# SMS_TIFS_ECC_AGGR_0_ECC_AGGR_43700000h register map
Vendor: Texas Instruments
Peripheral module from a debugger description file (folder AM275x).
Registers are 32-bit, access not given, reset 0x0 unless marked. A register's access mark holds for its fields unless they carry their own. Offsets are as the file gives them; lines under a group give offsets from that group; [hi:lo] are bit positions; {n}, {i} and the like mark numbered series; 'fields as' and 'values as' point back to an identical list; <NAME> marks a mode.

## ECC_AGGR
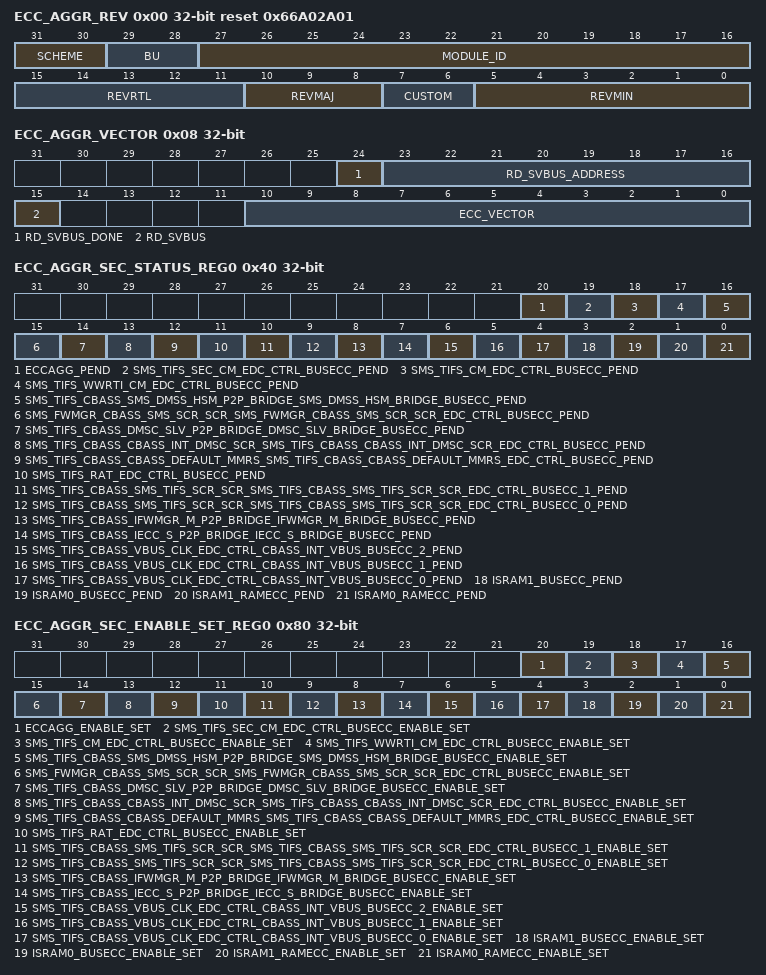
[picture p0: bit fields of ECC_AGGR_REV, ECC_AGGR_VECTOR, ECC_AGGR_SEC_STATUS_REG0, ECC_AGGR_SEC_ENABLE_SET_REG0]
0x00 ECC_AGGR_REV ro reset 0x66A02A01 — Revision parameters
  [31:30] SCHEME — Scheme Reset Source: sms_custom_rst_mod_g_rst_n
  [29:28] BU — Business Unit Reset Source: sms_custom_rst_mod_g_rst_n
  [27:16] MODULE_ID — Module ID Reset Source: sms_custom_rst_mod_g_rst_n
  [15:11] REVRTL — RTL version Reset Source: sms_custom_rst_mod_g_rst_n
  [10:8] REVMAJ — Major version Reset Source: sms_custom_rst_mod_g_rst_n
  [7:6] CUSTOM — Custom version Reset Source: sms_custom_rst_mod_g_rst_n
  [5:0] REVMIN — Minor version Reset Source: sms_custom_rst_mod_g_rst_n
0x08 ECC_AGGR_VECTOR — ECC Vector Register
  [24] RD_SVBUS_DONE — Status to indicate if read on serial VBUS is complete, write of any value will clear this bit. Reset Source: sms_custom_rst_mod_g_rst_n (access R/W1TC)
  [23:16] RD_SVBUS_ADDRESS rw — Read address Reset Source: sms_custom_rst_mod_g_rst_n
  [15] RD_SVBUS — Write 1 to trigger a read on the serial VBUS Reset Source: sms_custom_rst_mod_g_rst_n (access R/W1TS)
  [10:0] ECC_VECTOR rw — Value written to select the corresponding ECC RAM for control or status Reset Source: sms_custom_rst_mod_g_rst_n
0x0C ECC_AGGR_STAT ro reset 0x15 — Misc Status
  [10:0] NUM_RAMS — Indicates the number of RAMS serviced by the ECC aggregator Reset Source: sms_custom_rst_mod_g_rst_n
0x10 ECC_AGGR_RESERVED_SVBUS_j rw — Reference other documents that contain the ECC RAM wrapper and EDC controller serial vbus register sets.
  [31:0] DATA — Serial VBUS register data Reset Source: sms_custom_rst_mod_g_rst_n
0x3C ECC_AGGR_SEC_EOI_REG — EOI Register
  [0] EOI_WR — EOI Register Reset Source: sms_custom_rst_mod_g_rst_n (access R/W1TS)
0x40 ECC_AGGR_SEC_STATUS_REG0 — Interrupt Status Register 0
  [20] ECCAGG_PEND — Interrupt Pending Status for eccagg_pend Reset Source: sms_custom_rst_mod_g_rst_n (access R/W1TS)
  [19] SMS_TIFS_SEC_CM_EDC_CTRL_BUSECC_PEND — Interrupt Pending Status for sms_tifs_sec_cm_edc_ctrl_busecc_pend Reset Source: sms_custom_rst_mod_g_rst_n (access R/W1TS)
  [18] SMS_TIFS_CM_EDC_CTRL_BUSECC_PEND — Interrupt Pending Status for sms_tifs_cm_edc_ctrl_busecc_pend Reset Source: sms_custom_rst_mod_g_rst_n (access R/W1TS)
  [17] SMS_TIFS_WWRTI_CM_EDC_CTRL_BUSECC_PEND — Interrupt Pending Status for sms_tifs_wwrti_cm_edc_ctrl_busecc_pend Reset Source: sms_custom_rst_mod_g_rst_n (access R/W1TS)
  [16] SMS_TIFS_CBASS_SMS_DMSS_HSM_P2P_BRIDGE_SMS_DMSS_HSM_BRIDGE_BUSECC_PEND — Interrupt Pending Status for sms_tifs_cbass_sms_dmss_hsm_p2p_bridge_sms_dmss_hsm_bridge_busecc_pend Reset Source: sms_custom_rst_mod_g_rst_n (access R/W1TS)
  [15] SMS_FWMGR_CBASS_SMS_SCR_SCR_SMS_FWMGR_CBASS_SMS_SCR_SCR_EDC_CTRL_BUSECC_PEND — Interrupt Pending Status for sms_fwmgr_cbass_sms_scr_scr_sms_fwmgr_cbass_sms_scr_scr_edc_ctrl_busecc_pend Reset Source: sms_custom_rst_mod_g_rst_n (access R/W1TS)
  [14] SMS_TIFS_CBASS_DMSC_SLV_P2P_BRIDGE_DMSC_SLV_BRIDGE_BUSECC_PEND — Interrupt Pending Status for sms_tifs_cbass_dmsc_slv_p2p_bridge_dmsc_slv_bridge_busecc_pend Reset Source: sms_custom_rst_mod_g_rst_n (access R/W1TS)
  [13] SMS_TIFS_CBASS_CBASS_INT_DMSC_SCR_SMS_TIFS_CBASS_CBASS_INT_DMSC_SCR_EDC_CTRL_BUSECC_PEND — Interrupt Pending Status for sms_tifs_cbass_cbass_int_dmsc_scr_sms_tifs_cbass_cbass_int_dmsc_scr_edc_ctrl_busecc_pend Reset Source: sms_custom_rst_mod_g_rst_n (access R/W1TS)
  [12] SMS_TIFS_CBASS_CBASS_DEFAULT_MMRS_SMS_TIFS_CBASS_CBASS_DEFAULT_MMRS_EDC_CTRL_BUSECC_PEND — Interrupt Pending Status for sms_tifs_cbass_cbass_default_mmrs_sms_tifs_cbass_cbass_default_mmrs_edc_ctrl_busecc_pend Reset Source: sms_custom_rst_mod_g_rst_n (access R/W1TS)
  [11] SMS_TIFS_RAT_EDC_CTRL_BUSECC_PEND — Interrupt Pending Status for sms_tifs_rat_edc_ctrl_busecc_pend Reset Source: sms_custom_rst_mod_g_rst_n (access R/W1TS)
  [10] SMS_TIFS_CBASS_SMS_TIFS_SCR_SCR_SMS_TIFS_CBASS_SMS_TIFS_SCR_SCR_EDC_CTRL_BUSECC_1_PEND — Interrupt Pending Status for sms_tifs_cbass_sms_tifs_scr_scr_sms_tifs_cbass_sms_tifs_scr_scr_edc_ctrl_busecc_1_pend Reset Source: sms_custom_rst_mod_g_rst_n (access R/W1TS)
  [9] SMS_TIFS_CBASS_SMS_TIFS_SCR_SCR_SMS_TIFS_CBASS_SMS_TIFS_SCR_SCR_EDC_CTRL_BUSECC_0_PEND — Interrupt Pending Status for sms_tifs_cbass_sms_tifs_scr_scr_sms_tifs_cbass_sms_tifs_scr_scr_edc_ctrl_busecc_0_pend Reset Source: sms_custom_rst_mod_g_rst_n (access R/W1TS)
  [8] SMS_TIFS_CBASS_IFWMGR_M_P2P_BRIDGE_IFWMGR_M_BRIDGE_BUSECC_PEND — Interrupt Pending Status for sms_tifs_cbass_Ifwmgr_m_p2p_bridge_Ifwmgr_m_bridge_busecc_pend Reset Source: sms_custom_rst_mod_g_rst_n (access R/W1TS)
  [7] SMS_TIFS_CBASS_IECC_S_P2P_BRIDGE_IECC_S_BRIDGE_BUSECC_PEND — Interrupt Pending Status for sms_tifs_cbass_Iecc_s_p2p_bridge_Iecc_s_bridge_busecc_pend Reset Source: sms_custom_rst_mod_g_rst_n (access R/W1TS)
  [6] SMS_TIFS_CBASS_VBUS_CLK_EDC_CTRL_CBASS_INT_VBUS_BUSECC_2_PEND — Interrupt Pending Status for sms_tifs_cbass_vbus_clk_edc_ctrl_cbass_int_vbus_busecc_2_pend Reset Source: sms_custom_rst_mod_g_rst_n (access R/W1TS)
  [5] SMS_TIFS_CBASS_VBUS_CLK_EDC_CTRL_CBASS_INT_VBUS_BUSECC_1_PEND — Interrupt Pending Status for sms_tifs_cbass_vbus_clk_edc_ctrl_cbass_int_vbus_busecc_1_pend Reset Source: sms_custom_rst_mod_g_rst_n (access R/W1TS)
  [4] SMS_TIFS_CBASS_VBUS_CLK_EDC_CTRL_CBASS_INT_VBUS_BUSECC_0_PEND — Interrupt Pending Status for sms_tifs_cbass_vbus_clk_edc_ctrl_cbass_int_vbus_busecc_0_pend Reset Source: sms_custom_rst_mod_g_rst_n (access R/W1TS)
  [3] ISRAM1_BUSECC_PEND — Interrupt Pending Status for Isram1_busecc_pend Reset Source: sms_custom_rst_mod_g_rst_n (access R/W1TS)
  [2] ISRAM0_BUSECC_PEND — Interrupt Pending Status for Isram0_busecc_pend Reset Source: sms_custom_rst_mod_g_rst_n (access R/W1TS)
  [1] ISRAM1_RAMECC_PEND — Interrupt Pending Status for Isram1_ramecc_pend Reset Source: sms_custom_rst_mod_g_rst_n (access R/W1TS)
  [0] ISRAM0_RAMECC_PEND — Interrupt Pending Status for Isram0_ramecc_pend Reset Source: sms_custom_rst_mod_g_rst_n (access R/W1TS)
0x80 ECC_AGGR_SEC_ENABLE_SET_REG0 — Interrupt Enable Set Register 0
  [20] ECCAGG_ENABLE_SET — Interrupt Enable Set Register for eccagg_pend Reset Source: sms_custom_rst_mod_g_rst_n (access R/W1TS)
  [19] SMS_TIFS_SEC_CM_EDC_CTRL_BUSECC_ENABLE_SET — Interrupt Enable Set Register for sms_tifs_sec_cm_edc_ctrl_busecc_pend Reset Source: sms_custom_rst_mod_g_rst_n (access R/W1TS)
  [18] SMS_TIFS_CM_EDC_CTRL_BUSECC_ENABLE_SET — Interrupt Enable Set Register for sms_tifs_cm_edc_ctrl_busecc_pend Reset Source: sms_custom_rst_mod_g_rst_n (access R/W1TS)
  [17] SMS_TIFS_WWRTI_CM_EDC_CTRL_BUSECC_ENABLE_SET — Interrupt Enable Set Register for sms_tifs_wwrti_cm_edc_ctrl_busecc_pend Reset Source: sms_custom_rst_mod_g_rst_n (access R/W1TS)
  [16] SMS_TIFS_CBASS_SMS_DMSS_HSM_P2P_BRIDGE_SMS_DMSS_HSM_BRIDGE_BUSECC_ENABLE_SET — Interrupt Enable Set Register for sms_tifs_cbass_sms_dmss_hsm_p2p_bridge_sms_dmss_hsm_bridge_busecc_pend Reset Source: sms_custom_rst_mod_g_rst_n (access R/W1TS)
  [15] SMS_FWMGR_CBASS_SMS_SCR_SCR_SMS_FWMGR_CBASS_SMS_SCR_SCR_EDC_CTRL_BUSECC_ENABLE_SET — Interrupt Enable Set Register for sms_fwmgr_cbass_sms_scr_scr_sms_fwmgr_cbass_sms_scr_scr_edc_ctrl_busecc_pend Reset Source: sms_custom_rst_mod_g_rst_n (access R/W1TS)
  [14] SMS_TIFS_CBASS_DMSC_SLV_P2P_BRIDGE_DMSC_SLV_BRIDGE_BUSECC_ENABLE_SET — Interrupt Enable Set Register for sms_tifs_cbass_dmsc_slv_p2p_bridge_dmsc_slv_bridge_busecc_pend Reset Source: sms_custom_rst_mod_g_rst_n (access R/W1TS)
  [13] SMS_TIFS_CBASS_CBASS_INT_DMSC_SCR_SMS_TIFS_CBASS_CBASS_INT_DMSC_SCR_EDC_CTRL_BUSECC_ENABLE_SET — Interrupt Enable Set Register for sms_tifs_cbass_cbass_int_dmsc_scr_sms_tifs_cbass_cbass_int_dmsc_scr_edc_ctrl_busecc_pend Reset Source: sms_custom_rst_mod_g_rst_n (access R/W1TS)
  [12] SMS_TIFS_CBASS_CBASS_DEFAULT_MMRS_SMS_TIFS_CBASS_CBASS_DEFAULT_MMRS_EDC_CTRL_BUSECC_ENABLE_SET — Interrupt Enable Set Register for sms_tifs_cbass_cbass_default_mmrs_sms_tifs_cbass_cbass_default_mmrs_edc_ctrl_busecc_pend Reset Source: sms_custom_rst_mod_g_rst_n (access R/W1TS)
  [11] SMS_TIFS_RAT_EDC_CTRL_BUSECC_ENABLE_SET — Interrupt Enable Set Register for sms_tifs_rat_edc_ctrl_busecc_pend Reset Source: sms_custom_rst_mod_g_rst_n (access R/W1TS)
  [10] SMS_TIFS_CBASS_SMS_TIFS_SCR_SCR_SMS_TIFS_CBASS_SMS_TIFS_SCR_SCR_EDC_CTRL_BUSECC_1_ENABLE_SET — Interrupt Enable Set Register for sms_tifs_cbass_sms_tifs_scr_scr_sms_tifs_cbass_sms_tifs_scr_scr_edc_ctrl_busecc_1_pend Reset Source: sms_custom_rst_mod_g_rst_n (access R/W1TS)
  [9] SMS_TIFS_CBASS_SMS_TIFS_SCR_SCR_SMS_TIFS_CBASS_SMS_TIFS_SCR_SCR_EDC_CTRL_BUSECC_0_ENABLE_SET — Interrupt Enable Set Register for sms_tifs_cbass_sms_tifs_scr_scr_sms_tifs_cbass_sms_tifs_scr_scr_edc_ctrl_busecc_0_pend Reset Source: sms_custom_rst_mod_g_rst_n (access R/W1TS)
  [8] SMS_TIFS_CBASS_IFWMGR_M_P2P_BRIDGE_IFWMGR_M_BRIDGE_BUSECC_ENABLE_SET — Interrupt Enable Set Register for sms_tifs_cbass_Ifwmgr_m_p2p_bridge_Ifwmgr_m_bridge_busecc_pend Reset Source: sms_custom_rst_mod_g_rst_n (access R/W1TS)
  [7] SMS_TIFS_CBASS_IECC_S_P2P_BRIDGE_IECC_S_BRIDGE_BUSECC_ENABLE_SET — Interrupt Enable Set Register for sms_tifs_cbass_Iecc_s_p2p_bridge_Iecc_s_bridge_busecc_pend Reset Source: sms_custom_rst_mod_g_rst_n (access R/W1TS)
  [6] SMS_TIFS_CBASS_VBUS_CLK_EDC_CTRL_CBASS_INT_VBUS_BUSECC_2_ENABLE_SET — Interrupt Enable Set Register for sms_tifs_cbass_vbus_clk_edc_ctrl_cbass_int_vbus_busecc_2_pend Reset Source: sms_custom_rst_mod_g_rst_n (access R/W1TS)
  [5] SMS_TIFS_CBASS_VBUS_CLK_EDC_CTRL_CBASS_INT_VBUS_BUSECC_1_ENABLE_SET — Interrupt Enable Set Register for sms_tifs_cbass_vbus_clk_edc_ctrl_cbass_int_vbus_busecc_1_pend Reset Source: sms_custom_rst_mod_g_rst_n (access R/W1TS)
  [4] SMS_TIFS_CBASS_VBUS_CLK_EDC_CTRL_CBASS_INT_VBUS_BUSECC_0_ENABLE_SET — Interrupt Enable Set Register for sms_tifs_cbass_vbus_clk_edc_ctrl_cbass_int_vbus_busecc_0_pend Reset Source: sms_custom_rst_mod_g_rst_n (access R/W1TS)
  [3] ISRAM1_BUSECC_ENABLE_SET — Interrupt Enable Set Register for Isram1_busecc_pend Reset Source: sms_custom_rst_mod_g_rst_n (access R/W1TS)
  [2] ISRAM0_BUSECC_ENABLE_SET — Interrupt Enable Set Register for Isram0_busecc_pend Reset Source: sms_custom_rst_mod_g_rst_n (access R/W1TS)
  [1] ISRAM1_RAMECC_ENABLE_SET — Interrupt Enable Set Register for Isram1_ramecc_pend Reset Source: sms_custom_rst_mod_g_rst_n (access R/W1TS)
  [0] ISRAM0_RAMECC_ENABLE_SET — Interrupt Enable Set Register for Isram0_ramecc_pend Reset Source: sms_custom_rst_mod_g_rst_n (access R/W1TS)
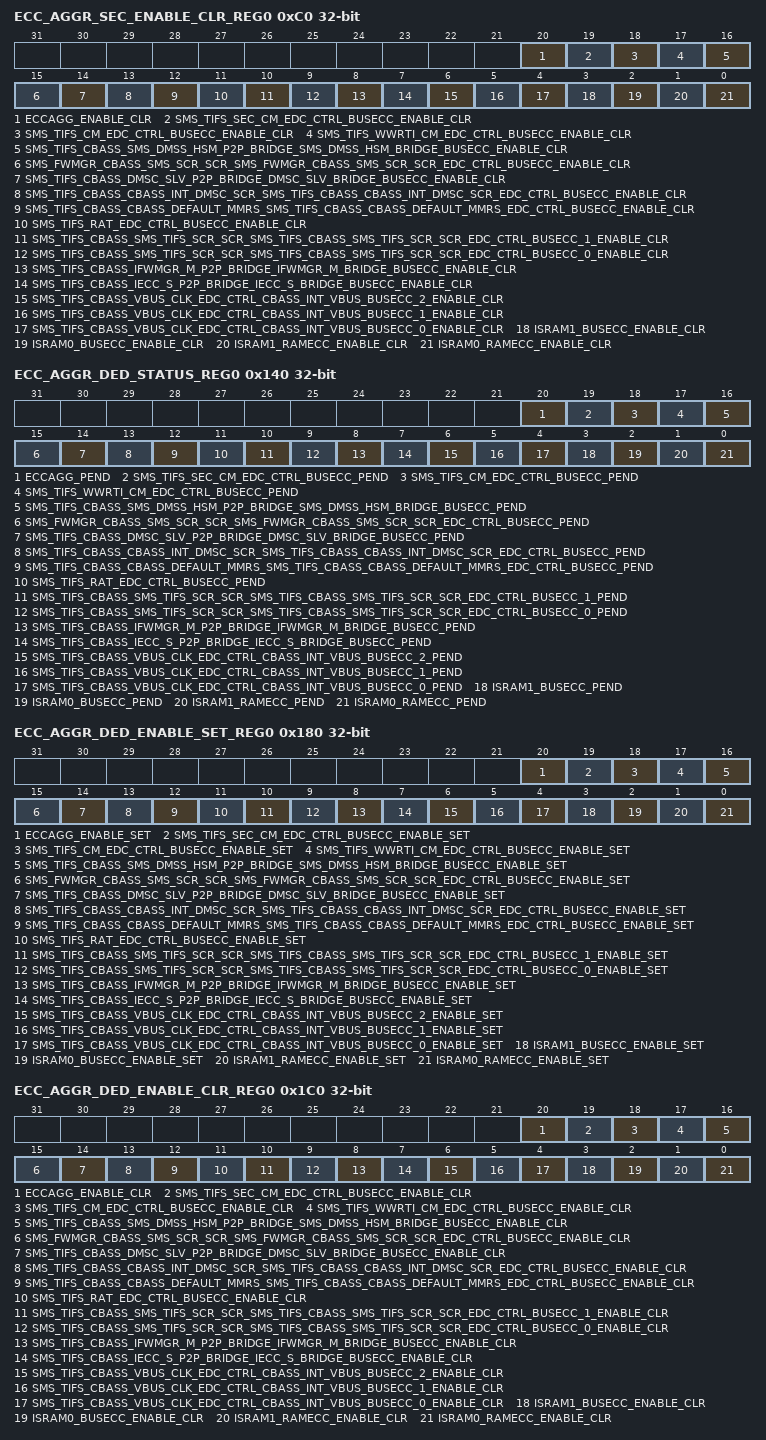
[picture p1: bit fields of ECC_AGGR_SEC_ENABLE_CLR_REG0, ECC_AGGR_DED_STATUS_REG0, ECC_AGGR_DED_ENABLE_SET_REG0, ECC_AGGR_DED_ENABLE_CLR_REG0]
0xC0 ECC_AGGR_SEC_ENABLE_CLR_REG0 — Interrupt Enable Clear Register 0
  [20] ECCAGG_ENABLE_CLR — Interrupt Enable Clear Register for eccagg_pend Reset Source: sms_custom_rst_mod_g_rst_n (access R/W1TC)
  [19] SMS_TIFS_SEC_CM_EDC_CTRL_BUSECC_ENABLE_CLR — Interrupt Enable Clear Register for sms_tifs_sec_cm_edc_ctrl_busecc_pend Reset Source: sms_custom_rst_mod_g_rst_n (access R/W1TC)
  [18] SMS_TIFS_CM_EDC_CTRL_BUSECC_ENABLE_CLR — Interrupt Enable Clear Register for sms_tifs_cm_edc_ctrl_busecc_pend Reset Source: sms_custom_rst_mod_g_rst_n (access R/W1TC)
  [17] SMS_TIFS_WWRTI_CM_EDC_CTRL_BUSECC_ENABLE_CLR — Interrupt Enable Clear Register for sms_tifs_wwrti_cm_edc_ctrl_busecc_pend Reset Source: sms_custom_rst_mod_g_rst_n (access R/W1TC)
  [16] SMS_TIFS_CBASS_SMS_DMSS_HSM_P2P_BRIDGE_SMS_DMSS_HSM_BRIDGE_BUSECC_ENABLE_CLR — Interrupt Enable Clear Register for sms_tifs_cbass_sms_dmss_hsm_p2p_bridge_sms_dmss_hsm_bridge_busecc_pend Reset Source: sms_custom_rst_mod_g_rst_n (access R/W1TC)
  [15] SMS_FWMGR_CBASS_SMS_SCR_SCR_SMS_FWMGR_CBASS_SMS_SCR_SCR_EDC_CTRL_BUSECC_ENABLE_CLR — Interrupt Enable Clear Register for sms_fwmgr_cbass_sms_scr_scr_sms_fwmgr_cbass_sms_scr_scr_edc_ctrl_busecc_pend Reset Source: sms_custom_rst_mod_g_rst_n (access R/W1TC)
  [14] SMS_TIFS_CBASS_DMSC_SLV_P2P_BRIDGE_DMSC_SLV_BRIDGE_BUSECC_ENABLE_CLR — Interrupt Enable Clear Register for sms_tifs_cbass_dmsc_slv_p2p_bridge_dmsc_slv_bridge_busecc_pend Reset Source: sms_custom_rst_mod_g_rst_n (access R/W1TC)
  [13] SMS_TIFS_CBASS_CBASS_INT_DMSC_SCR_SMS_TIFS_CBASS_CBASS_INT_DMSC_SCR_EDC_CTRL_BUSECC_ENABLE_CLR — Interrupt Enable Clear Register for sms_tifs_cbass_cbass_int_dmsc_scr_sms_tifs_cbass_cbass_int_dmsc_scr_edc_ctrl_busecc_pend Reset Source: sms_custom_rst_mod_g_rst_n (access R/W1TC)
  [12] SMS_TIFS_CBASS_CBASS_DEFAULT_MMRS_SMS_TIFS_CBASS_CBASS_DEFAULT_MMRS_EDC_CTRL_BUSECC_ENABLE_CLR — Interrupt Enable Clear Register for sms_tifs_cbass_cbass_default_mmrs_sms_tifs_cbass_cbass_default_mmrs_edc_ctrl_busecc_pend Reset Source: sms_custom_rst_mod_g_rst_n (access R/W1TC)
  [11] SMS_TIFS_RAT_EDC_CTRL_BUSECC_ENABLE_CLR — Interrupt Enable Clear Register for sms_tifs_rat_edc_ctrl_busecc_pend Reset Source: sms_custom_rst_mod_g_rst_n (access R/W1TC)
  [10] SMS_TIFS_CBASS_SMS_TIFS_SCR_SCR_SMS_TIFS_CBASS_SMS_TIFS_SCR_SCR_EDC_CTRL_BUSECC_1_ENABLE_CLR — Interrupt Enable Clear Register for sms_tifs_cbass_sms_tifs_scr_scr_sms_tifs_cbass_sms_tifs_scr_scr_edc_ctrl_busecc_1_pend Reset Source: sms_custom_rst_mod_g_rst_n (access R/W1TC)
  [9] SMS_TIFS_CBASS_SMS_TIFS_SCR_SCR_SMS_TIFS_CBASS_SMS_TIFS_SCR_SCR_EDC_CTRL_BUSECC_0_ENABLE_CLR — Interrupt Enable Clear Register for sms_tifs_cbass_sms_tifs_scr_scr_sms_tifs_cbass_sms_tifs_scr_scr_edc_ctrl_busecc_0_pend Reset Source: sms_custom_rst_mod_g_rst_n (access R/W1TC)
  [8] SMS_TIFS_CBASS_IFWMGR_M_P2P_BRIDGE_IFWMGR_M_BRIDGE_BUSECC_ENABLE_CLR — Interrupt Enable Clear Register for sms_tifs_cbass_Ifwmgr_m_p2p_bridge_Ifwmgr_m_bridge_busecc_pend Reset Source: sms_custom_rst_mod_g_rst_n (access R/W1TC)
  [7] SMS_TIFS_CBASS_IECC_S_P2P_BRIDGE_IECC_S_BRIDGE_BUSECC_ENABLE_CLR — Interrupt Enable Clear Register for sms_tifs_cbass_Iecc_s_p2p_bridge_Iecc_s_bridge_busecc_pend Reset Source: sms_custom_rst_mod_g_rst_n (access R/W1TC)
  [6] SMS_TIFS_CBASS_VBUS_CLK_EDC_CTRL_CBASS_INT_VBUS_BUSECC_2_ENABLE_CLR — Interrupt Enable Clear Register for sms_tifs_cbass_vbus_clk_edc_ctrl_cbass_int_vbus_busecc_2_pend Reset Source: sms_custom_rst_mod_g_rst_n (access R/W1TC)
  [5] SMS_TIFS_CBASS_VBUS_CLK_EDC_CTRL_CBASS_INT_VBUS_BUSECC_1_ENABLE_CLR — Interrupt Enable Clear Register for sms_tifs_cbass_vbus_clk_edc_ctrl_cbass_int_vbus_busecc_1_pend Reset Source: sms_custom_rst_mod_g_rst_n (access R/W1TC)
  [4] SMS_TIFS_CBASS_VBUS_CLK_EDC_CTRL_CBASS_INT_VBUS_BUSECC_0_ENABLE_CLR — Interrupt Enable Clear Register for sms_tifs_cbass_vbus_clk_edc_ctrl_cbass_int_vbus_busecc_0_pend Reset Source: sms_custom_rst_mod_g_rst_n (access R/W1TC)
  [3] ISRAM1_BUSECC_ENABLE_CLR — Interrupt Enable Clear Register for Isram1_busecc_pend Reset Source: sms_custom_rst_mod_g_rst_n (access R/W1TC)
  [2] ISRAM0_BUSECC_ENABLE_CLR — Interrupt Enable Clear Register for Isram0_busecc_pend Reset Source: sms_custom_rst_mod_g_rst_n (access R/W1TC)
  [1] ISRAM1_RAMECC_ENABLE_CLR — Interrupt Enable Clear Register for Isram1_ramecc_pend Reset Source: sms_custom_rst_mod_g_rst_n (access R/W1TC)
  [0] ISRAM0_RAMECC_ENABLE_CLR — Interrupt Enable Clear Register for Isram0_ramecc_pend Reset Source: sms_custom_rst_mod_g_rst_n (access R/W1TC)
0x13C ECC_AGGR_DED_EOI_REG — EOI Register
  fields as ECC_AGGR_SEC_EOI_REG
0x140 ECC_AGGR_DED_STATUS_REG0 — Interrupt Status Register 0
  fields as ECC_AGGR_SEC_STATUS_REG0
0x180 ECC_AGGR_DED_ENABLE_SET_REG0 — Interrupt Enable Set Register 0
  fields as ECC_AGGR_SEC_ENABLE_SET_REG0
0x1C0 ECC_AGGR_DED_ENABLE_CLR_REG0 — Interrupt Enable Clear Register 0
  fields as ECC_AGGR_SEC_ENABLE_CLR_REG0
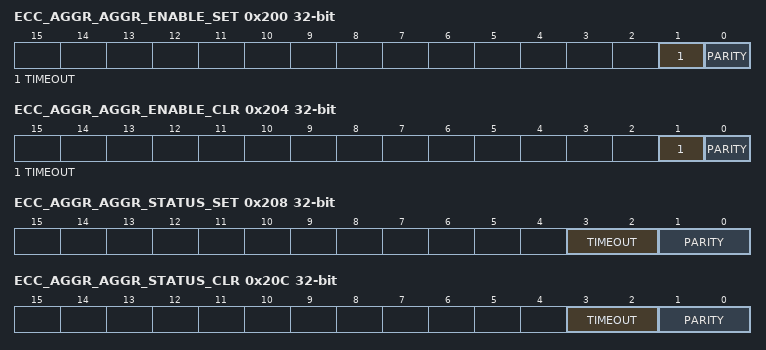
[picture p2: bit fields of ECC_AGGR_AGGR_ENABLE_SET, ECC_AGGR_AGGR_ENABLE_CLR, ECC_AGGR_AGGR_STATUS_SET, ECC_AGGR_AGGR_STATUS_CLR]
0x200 ECC_AGGR_AGGR_ENABLE_SET — AGGR interrupt enable set Register
  [1] TIMEOUT — interrupt enable set for svbus timeout errors Reset Source: sms_custom_rst_mod_g_rst_n (access R/W1TS)
  [0] PARITY — interrupt enable set for parity errors Reset Source: sms_custom_rst_mod_g_rst_n (access R/W1TS)
0x204 ECC_AGGR_AGGR_ENABLE_CLR — AGGR interrupt enable clear Register
  [1] TIMEOUT — interrupt enable clear for svbus timeout errors Reset Source: sms_custom_rst_mod_g_rst_n (access R/W1TC)
  [0] PARITY — interrupt enable clear for parity errors Reset Source: sms_custom_rst_mod_g_rst_n (access R/W1TC)
0x208 ECC_AGGR_AGGR_STATUS_SET — AGGR interrupt status set Register
  [3:2] TIMEOUT — interrupt status set for svbus timeout errors Reset Source: sms_custom_rst_mod_g_rst_n (access R/WI)
  [1:0] PARITY — interrupt status set for parity errors Reset Source: sms_custom_rst_mod_g_rst_n (access R/WI)
0x20C ECC_AGGR_AGGR_STATUS_CLR — AGGR interrupt status clear Register
  [3:2] TIMEOUT — interrupt status clear for svbus timeout errors Reset Source: sms_custom_rst_mod_g_rst_n (access R/WD)
  [1:0] PARITY — interrupt status clear for parity errors Reset Source: sms_custom_rst_mod_g_rst_n (access R/WD)
